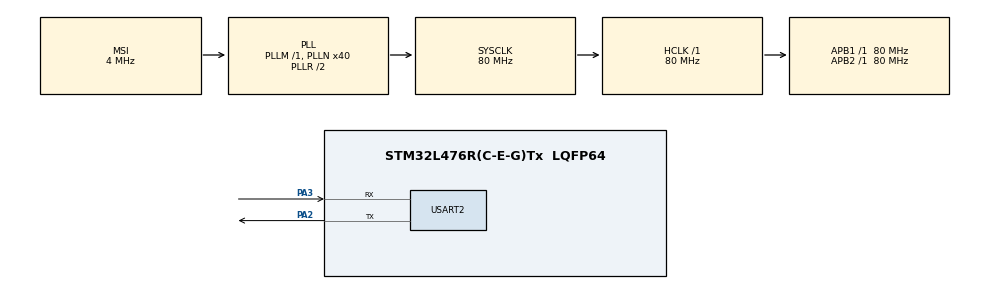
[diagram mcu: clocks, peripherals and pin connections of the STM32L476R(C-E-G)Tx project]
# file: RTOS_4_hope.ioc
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FREERTOS.Tasks01=defaultTask,0,128,StartDefaultTask,Default,NULL,Dynamic,NULL,NULL
FREERTOS.configUSE_COUNTING_SEMAPHORES=1
Mcu.Family=STM32L4
Mcu.Name=STM32L476R(C-E-G)Tx
Mcu.Package=LQFP64
NVIC.PriorityGroup=NVIC_PRIORITYGROUP_4
NVIC.TIM1_UP_TIM16_IRQn=true\:0\:0\:false\:false\:true\:false\:false\:true
NVIC.TimeBase=TIM1_UP_TIM16_IRQn
NVIC.TimeBaseIP=TIM1
NVIC.USART2_IRQn=true\:5\:0\:false\:false\:true\:true\:true\:true
PA2.Mode=Asynchronous
PA2.Signal=USART2_TX
PA3.Mode=Asynchronous
PA3.Signal=USART2_RX
ProjectManager.HeapSize=0x200
ProjectManager.StackSize=0x400
ProjectManager.TargetToolchain=TrueSTUDIO
RCC.AHBFreq_Value=80000000
RCC.APB1Freq_Value=80000000
RCC.APB1TimFreq_Value=80000000
RCC.APB2Freq_Value=80000000
RCC.APB2TimFreq_Value=80000000
RCC.CortexFreq_Value=80000000
RCC.HCLKFreq_Value=80000000
RCC.HSE_VALUE=8000000
RCC.HSI_VALUE=16000000
RCC.LSE_VALUE=32768
RCC.MSI_VALUE=4000000
RCC.PLLN=40
RCC.SYSCLKFreq_VALUE=80000000
RCC.SYSCLKSource=RCC_SYSCLKSOURCE_PLLCLK
RCC.VCOOutputFreq_Value=160000000
USART2.VirtualMode-Asynchronous=VM_ASYNC
VP_FREERTOS_VS_CMSIS_V1.Mode=CMSIS_V1
VP_SYS_VS_tim1.Mode=TIM1
board=custom

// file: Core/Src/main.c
/* USER CODE BEGIN Header */
/**
  ******************************************************************************
  * @file           : main.c
  * @brief          : Main program body
  ******************************************************************************
  * @attention
  *
  * <h2><center>&copy; Copyright (c) 2021 STMicroelectronics.
  * All rights reserved.</center></h2>
  *
  * This software component is licensed by ST under Ultimate Liberty license
  * SLA0044, the "License"; You may not use this file except in compliance with
  * the License. You may obtain a copy of the License at:
  *                             www.st.com/SLA0044
  *
  ******************************************************************************
  */
/* USER CODE END Header */
#include "main.h"
//#include "cmsis_os.h"

/* USER CODE BEGIN Includes */
#include "FreeRTOS.h"
#include "task.h"
#include "timers.h"
#include "queue.h"
#include "semphr.h"
#include "event_groups.h"

#include "stdlib.h"
#include "string.h"
/* USER CODE END Includes */

UART_HandleTypeDef huart2;

//osThreadId defaultTaskHandle;

void SystemClock_Config(void);
static void MX_GPIO_Init(void);
static void MX_USART2_UART_Init(void);
//void StartDefaultTask(void const * argument);

/* USER CODE BEGIN 0 */

// create task defines

TaskHandle_t HPThandler;
void HPT_TASK(void *pvParameters);

TaskHandle_t MPThandler;
void MPT_TASK(void *pvParameters);

TaskHandle_t LPThandler;
void LPT_TASK(void *pvParameters);

TaskHandle_t VLPThandler;
void VLPT_TASK(void *pvParameters);

//semaphore relate
SemaphoreHandle_t CountingSem;

//resource relate
int resource[3]={111,222,333};
int indx=0;

//uart relate
uint8_t rx_data=0;
/* USER CODE END 0 */

int main(void)
{

  /* MCU Configuration--------------------------------------------------------*/

  /* Reset of all peripherals, Initializes the Flash interface and the Systick. */
  HAL_Init();

  /* Configure the system clock */
  SystemClock_Config();

  /* Initialize all configured peripherals */
  MX_GPIO_Init();
  MX_USART2_UART_Init();
  /* USER CODE BEGIN 2 */
  HAL_UART_Receive_IT(&huart2, &rx_data, 1);

  CountingSem=xSemaphoreCreateCounting(3,0);
  if(CountingSem==NULL)
  {
	  HAL_UART_Transmit(&huart2,(uint8_t *) "Unable to create Semaphore\r\n",28,100);
  }
  else
  {
	  HAL_UART_Transmit(&huart2,(uint8_t *) "Counting Semaphore create successfully\r\n",41,1000);
  }

  //creat task
  xTaskCreate(HPT_TASK,"HPT",128, NULL, 3, &HPThandler);
  xTaskCreate(MPT_TASK,"MPT",128, NULL, 2, &MPThandler);
  xTaskCreate(LPT_TASK,"LPT",128, NULL, 1, &LPThandler);
  xTaskCreate(VLPT_TASK,"VLPT",128, NULL, 0, &VLPThandler);

  vTaskStartScheduler();

  /* USER CODE END 2 */

  /* We should never get here as control is now taken by the scheduler */
  /* Infinite loop */
  while (1)
  {

  }
}

void SystemClock_Config(void)
{
  RCC_OscInitTypeDef RCC_OscInitStruct = {0};
  RCC_ClkInitTypeDef RCC_ClkInitStruct = {0};
  RCC_PeriphCLKInitTypeDef PeriphClkInit = {0};

  /** Initializes the RCC Oscillators according to the specified parameters
  * in the RCC_OscInitTypeDef structure.
  */
  RCC_OscInitStruct.OscillatorType = RCC_OSCILLATORTYPE_MSI;
  RCC_OscInitStruct.MSIState = RCC_MSI_ON;
  RCC_OscInitStruct.MSICalibrationValue = 0;
  RCC_OscInitStruct.MSIClockRange = RCC_MSIRANGE_6;
  RCC_OscInitStruct.PLL.PLLState = RCC_PLL_ON;
  RCC_OscInitStruct.PLL.PLLSource = RCC_PLLSOURCE_MSI;
  RCC_OscInitStruct.PLL.PLLM = 1;
  RCC_OscInitStruct.PLL.PLLN = 40;
  RCC_OscInitStruct.PLL.PLLP = RCC_PLLP_DIV7;
  RCC_OscInitStruct.PLL.PLLQ = RCC_PLLQ_DIV2;
  RCC_OscInitStruct.PLL.PLLR = RCC_PLLR_DIV2;
  if (HAL_RCC_OscConfig(&RCC_OscInitStruct) != HAL_OK)
  {
    Error_Handler();
  }
  /** Initializes the CPU, AHB and APB buses clocks
  */
  RCC_ClkInitStruct.ClockType = RCC_CLOCKTYPE_HCLK|RCC_CLOCKTYPE_SYSCLK
                              |RCC_CLOCKTYPE_PCLK1|RCC_CLOCKTYPE_PCLK2;
  RCC_ClkInitStruct.SYSCLKSource = RCC_SYSCLKSOURCE_PLLCLK;
  RCC_ClkInitStruct.AHBCLKDivider = RCC_SYSCLK_DIV1;
  RCC_ClkInitStruct.APB1CLKDivider = RCC_HCLK_DIV1;
  RCC_ClkInitStruct.APB2CLKDivider = RCC_HCLK_DIV1;

  if (HAL_RCC_ClockConfig(&RCC_ClkInitStruct, FLASH_LATENCY_4) != HAL_OK)
  {
    Error_Handler();
  }
  PeriphClkInit.PeriphClockSelection = RCC_PERIPHCLK_USART2;
  PeriphClkInit.Usart2ClockSelection = RCC_USART2CLKSOURCE_PCLK1;
  if (HAL_RCCEx_PeriphCLKConfig(&PeriphClkInit) != HAL_OK)
  {
    Error_Handler();
  }
  /** Configure the main internal regulator output voltage
  */
  if (HAL_PWREx_ControlVoltageScaling(PWR_REGULATOR_VOLTAGE_SCALE1) != HAL_OK)
  {
    Error_Handler();
  }
}

static void MX_USART2_UART_Init(void)
{

  huart2.Instance = USART2;
  huart2.Init.BaudRate = 115200;
  huart2.Init.WordLength = UART_WORDLENGTH_8B;
  huart2.Init.StopBits = UART_STOPBITS_1;
  huart2.Init.Parity = UART_PARITY_NONE;
  huart2.Init.Mode = UART_MODE_TX_RX;
  huart2.Init.HwFlowCtl = UART_HWCONTROL_NONE;
  huart2.Init.OverSampling = UART_OVERSAMPLING_16;
  huart2.Init.OneBitSampling = UART_ONE_BIT_SAMPLE_DISABLE;
  huart2.AdvancedInit.AdvFeatureInit = UART_ADVFEATURE_NO_INIT;
  if (HAL_UART_Init(&huart2) != HAL_OK)
  {
    Error_Handler();
  }

}

static void MX_GPIO_Init(void)
{

  /* GPIO Ports Clock Enable */
  __HAL_RCC_GPIOA_CLK_ENABLE();

}

/* USER CODE BEGIN 4 */
void HPT_TASK(void *pvParameters)
{
	char sresource[3];
	// give 3 semaphore at the beginning
	/*xSemaphoreGive(CountingSem);
	xSemaphoreGive(CountingSem);
	xSemaphoreGive(CountingSem);*/

	while(1)
	{
		char str[150];
		strcpy(str,"Entered HPT Task\r\n About to AQUIRE the Semaphore\r\n");
		HAL_UART_Transmit(&huart2, (uint8_t *)str, strlen (str), HAL_MAX_DELAY);

		xSemaphoreTake(CountingSem,portMAX_DELAY);
		//portMAX_DELAY means wait forever until semaphore available

		itoa (resource[indx], sresource, 10);
		//itoa convert int to string
		strcpy (str, "Leaving HPT Task\r\n Data ACCESSED is :: ");
		strcat (str, sresource);
		strcat (str, "\r\n Not releasing the Semaphore\r\n\r\n\r\n");
		HAL_UART_Transmit(&huart2, (uint8_t *)str, strlen (str), HAL_MAX_DELAY);

		indx++;
		if (indx>2) indx = 0;

		//vTaskDelay(3000);
		vTaskDelete(NULL);
	}
}

void MPT_TASK(void *pvParameters)
{
	char sresource[3];

	while(1)
	{
		char str[150];
		strcpy(str,"Entered MPT Task\r\n About to AQUIRE the Semaphore\r\n");
		HAL_UART_Transmit(&huart2, (uint8_t *)str, strlen (str), HAL_MAX_DELAY);

		xSemaphoreTake(CountingSem,portMAX_DELAY);
		//portMAX_DELAY means wait forever until semaphore available

		itoa (resource[indx], sresource, 10);
		//itoa convert int to string
		strcpy (str, "Leaving MPT Task\r\n Data ACCESSED is :: ");
		strcat (str, sresource);
		strcat (str, "\r\n Not releasing the Semaphore\r\n\r\n\r\n");
		HAL_UART_Transmit(&huart2, (uint8_t *)str, strlen (str), HAL_MAX_DELAY);

		indx++;
		if (indx>2) indx = 0;

		//vTaskDelay(2000);
		vTaskDelete(NULL);
	}
}

void LPT_TASK(void *pvParameters)
{
	char sresource[3];

	while(1)
	{
		char str[150];
		strcpy(str,"Entered LPT Task\r\n About to AQUIRE the Semaphore\r\n");
		HAL_UART_Transmit(&huart2, (uint8_t *)str, strlen (str), HAL_MAX_DELAY);

		xSemaphoreTake(CountingSem,portMAX_DELAY);
		//portMAX_DELAY means wait forever until semaphore available

		itoa (resource[indx], sresource, 10);
		//itoa convert int to string
		strcpy (str, "Leaving LPT Task\r\n Data ACCESSED is :: ");
		strcat (str, sresource);
		strcat (str, "\r\n Not releasing the Semaphore\r\n\r\n\r\n");
		HAL_UART_Transmit(&huart2, (uint8_t *)str, strlen (str), HAL_MAX_DELAY);

		indx++;
		if (indx>2) indx = 0;

		//vTaskDelay(1000);
		vTaskDelete(NULL);
	}
}

void VLPT_TASK(void *pvParameters)
{
	char sresource[3];

	while(1)
	{
		char str[150];
		strcpy(str,"Entered VLPT Task\r\n About to AQUIRE the Semaphore\r\n");
		HAL_UART_Transmit(&huart2, (uint8_t *)str, strlen (str), HAL_MAX_DELAY);

		xSemaphoreTake(CountingSem,portMAX_DELAY);
		//portMAX_DELAY means wait forever until semaphore available

		itoa (resource[indx], sresource, 10);
		//itoa convert int to string
		strcpy (str, "Leaving VLPT Task\r\n Data ACCESSED is :: ");
		strcat (str, sresource);
		strcat (str, "\r\n Not releasing the Semaphore\r\n\r\n\r\n");
		HAL_UART_Transmit(&huart2, (uint8_t *)str, strlen (str), HAL_MAX_DELAY);

		indx++;
		if (indx>2) indx = 0;

		vTaskDelay(3000);

	}
}

void HAL_UART_RxCpltCallback(UART_HandleTypeDef *huart)
{
	HAL_UART_Receive_IT(huart, &rx_data, 1);
	if (rx_data == 'r')
	{
		// release the semaphore here
		 /* The xHigherPriorityTaskWoken parameter must be initialized to pdFALSE as
		 it will get set to pdTRUE inside the interrupt safe API function if a
		 context switch is required. */
		BaseType_t xHigherPriorityTaskWoken = pdFALSE;

		xSemaphoreGiveFromISR(CountingSem, &xHigherPriorityTaskWoken);  // ISR SAFE VERSION
		xSemaphoreGiveFromISR(CountingSem, &xHigherPriorityTaskWoken);  // ISR SAFE VERSION
		xSemaphoreGiveFromISR(CountingSem, &xHigherPriorityTaskWoken);  // ISR SAFE VERSION

		/* Pass the xHigherPriorityTaskWoken value into portEND_SWITCHING_ISR(). If
		 xHigherPriorityTaskWoken was set to pdTRUE inside xSemaphoreGiveFromISR()
		 then calling portEND_SWITCHING_ISR() will request a context switch. If
		 xHigherPriorityTaskWoken is still pdFALSE then calling
		 portEND_SWITCHING_ISR() will have no effect */

		portEND_SWITCHING_ISR( xHigherPriorityTaskWoken );
	}
}
/* USER CODE END 4 */

 /**
  * @brief  Period elapsed callback in non blocking mode
  * @note   This function is called  when TIM1 interrupt took place, inside
  * HAL_TIM_IRQHandler(). It makes a direct call to HAL_IncTick() to increment
  * a global variable "uwTick" used as application time base.
  * @param  htim : TIM handle
  * @retval None
  */
void HAL_TIM_PeriodElapsedCallback(TIM_HandleTypeDef *htim)
{
  if (htim->Instance == TIM1) {
    HAL_IncTick();
  }
}

void Error_Handler(void)
{
  __disable_irq();
  while (1)
  {
  }
}

/************************ (C) COPYRIGHT STMicroelectronics *****END OF FILE****/
